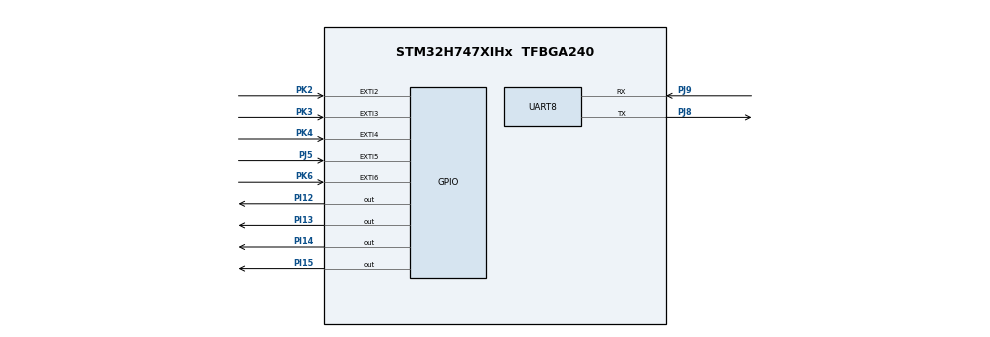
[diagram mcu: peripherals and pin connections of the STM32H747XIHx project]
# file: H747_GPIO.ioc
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Mcu.Family=STM32H7
PK3.Signal=GPXTI3
RCC.CortexFreq_Value=8000000
PJ9.Mode=Asynchronous
PI15.PinState=GPIO_PIN_SET
ProjectManager.StackSize=0x400
PK6.GPIO_PuPd=GPIO_NOPULL
PK6.PinAttribute=CortexM7
PK4.PinAttribute=CortexM7
PI13.PinState=GPIO_PIN_SET
RCC.HCLKFreq_Value=8000000
PI13.Signal=GPIO_Output
PJ5.GPIO_ModeDefaultEXTI=GPIO_MODE_IT_FALLING
NVIC2.PriorityGroup=NVIC_PRIORITYGROUP_4
PI12.PinAttribute=CortexM7
VP_SYS_M4_VS_Systick.Mode=SysTick
PK4.GPIO_ModeDefaultEXTI=GPIO_MODE_IT_FALLING
CortexM7.Pins=PK4,PK6,PK3,PI12,PI13,PI14,PK2,PI15,PJ5
CortexM7.IPs=BDMA\:I,CORTEX_M7\:I,DEBUG\:I,DMA\:I,FATFS_M7\:I,FREERTOS_M7\:I,IWDG1\:I,MDMA\:I,NVIC1\:I,OPENAMP_M7\:I,PDM2PCM_M7\:I,PWR\:I,RCC\:I,RESMGR_UTILITY\:I,SYS\:I,USB_DEVICE_M7\:I,USB_HOST_M7\:I,VREFBUF\:I,WWDG1\:I,UART8\:I
PK6.GPIO_ModeDefaultEXTI=GPIO_MODE_IT_FALLING
PJ5.PinAttribute=CortexM7
PJ5.GPIO_PuPd=GPIO_PULLDOWN
RCC.APB3Freq_Value=8000000
Mcu.Package=TFBGA240
PJ9.PinAttribute=CortexM7
PJ9.Signal=UART8_RX
PK2.GPIO_PuPd=GPIO_NOPULL
RCC.APB4Freq_Value=8000000
PK6.Signal=GPXTI6
PK4.Signal=GPXTI4
PK2.Signal=GPXTI2
PI14.PinState=GPIO_PIN_SET
RCC.D1CPRE=RCC_SYSCLK_DIV8
PJ8.Mode=Asynchronous
NVIC1.EXTI9_5_IRQn=true\:0\:0\:false\:false\:true\:true\:true
PI14.Signal=GPIO_Output
PI15.PinAttribute=CortexM7
PI14.PinAttribute=CortexM7
NVIC1.PriorityGroup=NVIC_PRIORITYGROUP_4
PI12.Signal=GPIO_Output
PJ8.PinAttribute=CortexM7
PK2.GPIO_ModeDefaultEXTI=GPIO_MODE_IT_FALLING
PK2.PinAttribute=CortexM7
ProjectManager.TargetToolchain=STM32CubeIDE
PI13.PinAttribute=CortexM7
NVIC1.EXTI2_IRQn=true\:0\:0\:false\:false\:true\:true\:true
RCC.USBFreq_Value=129000000
PK3.GPIO_PuPd=GPIO_NOPULL
board=custom
PK4.GPIO_PuPd=GPIO_NOPULL
RCC.APB2Freq_Value=8000000
PK3.PinAttribute=CortexM7
RCC.ADCFreq_Value=129000000
Mcu.Name=STM32H747XIHx
RCC.SYSCLKFreq_VALUE=64000000
PK3.GPIO_ModeDefaultEXTI=GPIO_MODE_IT_FALLING
NVIC1.EXTI4_IRQn=true\:0\:0\:false\:false\:true\:true\:true
PJ5.Signal=GPXTI5
PJ8.Signal=UART8_TX
ProjectManager.HeapSize=0x200
NVIC1.EXTI3_IRQn=true\:0\:0\:false\:false\:true\:true\:true
PI15.Signal=GPIO_Output
RCC.APB1Freq_Value=8000000
PI12.PinState=GPIO_PIN_SET
CortexM4.IPs=BDMA,CORTEX_M4\:I,DEBUG,DMA,FATFS_M4\:I,FREERTOS_M4\:I,IWDG2\:I,MDMA,NVIC2\:I,OPENAMP_M4\:I,PDM2PCM_M4\:I,PWR,RCC,RESMGR_UTILITY,SYS_M4\:I,USB_DEVICE_M4\:I,USB_HOST_M4\:I,VREFBUF,WWDG2\:I

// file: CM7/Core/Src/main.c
/* USER CODE BEGIN Header */
/**
  ******************************************************************************
  * @file           : main.c
  * @brief          : Main program body
  ******************************************************************************
  * @attention
  *
  * <h2><center>&copy; Copyright (c) 2020 STMicroelectronics.
  * All rights reserved.</center></h2>
  *
  * This software component is licensed by ST under BSD 3-Clause license,
  * the "License"; You may not use this file except in compliance with the
  * License. You may obtain a copy of the License at:
  *                        opensource.org/licenses/BSD-3-Clause
  *
  ******************************************************************************
  */
/* USER CODE END Header */
#include "main.h"
#include <stdio.h>

/* USER CODE BEGIN PD */

#define HSEM_ID_0 (0U) /* HW semaphore 0*/
/* USER CODE END PD */

UART_HandleTypeDef huart8;

/* USER CODE BEGIN PV */

int __io_putchar (int ch) {
	uint8_t c = ch;
	HAL_UART_Transmit(&huart8, &c, 1, HAL_MAX_DELAY);
	return ch;
}
void HAL_GPIO_EXTI_Callback(uint16_t GPIO_Pin)
{
	if(GPIO_Pin == GPIO_PIN_2){
		printf("***2***\r\n");
	}
	if(GPIO_Pin == GPIO_PIN_3){
		printf("***3***\r\n");
	}
	if(GPIO_Pin == GPIO_PIN_4){
		printf("***4***\r\n");
	}
	if(GPIO_Pin == GPIO_PIN_5){
		printf("***5***\r\n");
	}
}
/* USER CODE END PV */

void SystemClock_Config(void);
static void MX_GPIO_Init(void);
static void MX_UART8_Init(void);

int main(void)
{

/* USER CODE BEGIN Boot_Mode_Sequence_0 */
  int32_t timeout;
/* USER CODE END Boot_Mode_Sequence_0 */

/* USER CODE BEGIN Boot_Mode_Sequence_1 */
  /* Wait until CPU2 boots and enters in stop mode or timeout*/
  timeout = 0xFFFF;
  while((__HAL_RCC_GET_FLAG(RCC_FLAG_D2CKRDY) != RESET) && (timeout-- > 0));
  if ( timeout < 0 )
  {
  Error_Handler();
  }
/* USER CODE END Boot_Mode_Sequence_1 */
  /* MCU Configuration--------------------------------------------------------*/

  /* Reset of all peripherals, Initializes the Flash interface and the Systick. */
  HAL_Init();

  /* Configure the system clock */
  SystemClock_Config();
/* USER CODE BEGIN Boot_Mode_Sequence_2 */
/* When system initialization is finished, Cortex-M7 will release Cortex-M4 by means of
HSEM notification */
/*HW semaphore Clock enable*/
__HAL_RCC_HSEM_CLK_ENABLE();
/*Take HSEM */
HAL_HSEM_FastTake(HSEM_ID_0);
/*Release HSEM in order to notify the CPU2(CM4)*/
HAL_HSEM_Release(HSEM_ID_0,0);
/* wait until CPU2 wakes up from stop mode */
timeout = 0xFFFF;
while((__HAL_RCC_GET_FLAG(RCC_FLAG_D2CKRDY) == RESET) && (timeout-- > 0));
if ( timeout < 0 )
{
Error_Handler();
}
/* USER CODE END Boot_Mode_Sequence_2 */

  /* Initialize all configured peripherals */
  MX_GPIO_Init();
  MX_UART8_Init();

  /* Infinite loop */
  while (1)
  {

  }
}

void SystemClock_Config(void)
{
  RCC_OscInitTypeDef RCC_OscInitStruct = {0};
  RCC_ClkInitTypeDef RCC_ClkInitStruct = {0};
  RCC_PeriphCLKInitTypeDef PeriphClkInitStruct = {0};

  /** Supply configuration update enable
  */
  HAL_PWREx_ConfigSupply(PWR_LDO_SUPPLY);
  /** Configure the main internal regulator output voltage
  */
  __HAL_PWR_VOLTAGESCALING_CONFIG(PWR_REGULATOR_VOLTAGE_SCALE3);

  while(!__HAL_PWR_GET_FLAG(PWR_FLAG_VOSRDY)) {}
  /** Initializes the RCC Oscillators according to the specified parameters
  * in the RCC_OscInitTypeDef structure.
  */
  RCC_OscInitStruct.OscillatorType = RCC_OSCILLATORTYPE_HSI;
  RCC_OscInitStruct.HSIState = RCC_HSI_DIV1;
  RCC_OscInitStruct.HSICalibrationValue = RCC_HSICALIBRATION_DEFAULT;
  RCC_OscInitStruct.PLL.PLLState = RCC_PLL_NONE;
  if (HAL_RCC_OscConfig(&RCC_OscInitStruct) != HAL_OK)
  {
    Error_Handler();
  }
  /** Initializes the CPU, AHB and APB buses clocks
  */
  RCC_ClkInitStruct.ClockType = RCC_CLOCKTYPE_HCLK|RCC_CLOCKTYPE_SYSCLK
                              |RCC_CLOCKTYPE_PCLK1|RCC_CLOCKTYPE_PCLK2
                              |RCC_CLOCKTYPE_D3PCLK1|RCC_CLOCKTYPE_D1PCLK1;
  RCC_ClkInitStruct.SYSCLKSource = RCC_SYSCLKSOURCE_HSI;
  RCC_ClkInitStruct.SYSCLKDivider = RCC_SYSCLK_DIV8;
  RCC_ClkInitStruct.AHBCLKDivider = RCC_HCLK_DIV1;
  RCC_ClkInitStruct.APB3CLKDivider = RCC_APB3_DIV1;
  RCC_ClkInitStruct.APB1CLKDivider = RCC_APB1_DIV1;
  RCC_ClkInitStruct.APB2CLKDivider = RCC_APB2_DIV1;
  RCC_ClkInitStruct.APB4CLKDivider = RCC_APB4_DIV1;

  if (HAL_RCC_ClockConfig(&RCC_ClkInitStruct, FLASH_LATENCY_0) != HAL_OK)
  {
    Error_Handler();
  }
  PeriphClkInitStruct.PeriphClockSelection = RCC_PERIPHCLK_UART8;
  PeriphClkInitStruct.Usart234578ClockSelection = RCC_USART234578CLKSOURCE_D2PCLK1;
  if (HAL_RCCEx_PeriphCLKConfig(&PeriphClkInitStruct) != HAL_OK)
  {
    Error_Handler();
  }
}

static void MX_UART8_Init(void)
{

  huart8.Instance = UART8;
  huart8.Init.BaudRate = 115200;
  huart8.Init.WordLength = UART_WORDLENGTH_8B;
  huart8.Init.StopBits = UART_STOPBITS_1;
  huart8.Init.Parity = UART_PARITY_NONE;
  huart8.Init.Mode = UART_MODE_TX_RX;
  huart8.Init.HwFlowCtl = UART_HWCONTROL_NONE;
  huart8.Init.OverSampling = UART_OVERSAMPLING_16;
  huart8.Init.OneBitSampling = UART_ONE_BIT_SAMPLE_DISABLE;
  huart8.Init.ClockPrescaler = UART_PRESCALER_DIV1;
  huart8.AdvancedInit.AdvFeatureInit = UART_ADVFEATURE_NO_INIT;
  if (HAL_UART_Init(&huart8) != HAL_OK)
  {
    Error_Handler();
  }
  if (HAL_UARTEx_SetTxFifoThreshold(&huart8, UART_TXFIFO_THRESHOLD_1_8) != HAL_OK)
  {
    Error_Handler();
  }
  if (HAL_UARTEx_SetRxFifoThreshold(&huart8, UART_RXFIFO_THRESHOLD_1_8) != HAL_OK)
  {
    Error_Handler();
  }
  if (HAL_UARTEx_DisableFifoMode(&huart8) != HAL_OK)
  {
    Error_Handler();
  }

}

static void MX_GPIO_Init(void)
{
  GPIO_InitTypeDef GPIO_InitStruct = {0};

  /* GPIO Ports Clock Enable */
  __HAL_RCC_GPIOK_CLK_ENABLE();
  __HAL_RCC_GPIOI_CLK_ENABLE();
  __HAL_RCC_GPIOJ_CLK_ENABLE();

  /*Configure GPIO pin Output Level */
  HAL_GPIO_WritePin(GPIOI, GPIO_PIN_12|GPIO_PIN_13|GPIO_PIN_14|GPIO_PIN_15, GPIO_PIN_SET);

  /*Configure GPIO pins : PK4 PK6 PK3 PK2 */
  GPIO_InitStruct.Pin = GPIO_PIN_4|GPIO_PIN_6|GPIO_PIN_3|GPIO_PIN_2;
  GPIO_InitStruct.Mode = GPIO_MODE_IT_FALLING;
  GPIO_InitStruct.Pull = GPIO_NOPULL;
  HAL_GPIO_Init(GPIOK, &GPIO_InitStruct);

  /*Configure GPIO pins : PI12 PI13 PI14 PI15 */
  GPIO_InitStruct.Pin = GPIO_PIN_12|GPIO_PIN_13|GPIO_PIN_14|GPIO_PIN_15;
  GPIO_InitStruct.Mode = GPIO_MODE_OUTPUT_PP;
  GPIO_InitStruct.Pull = GPIO_NOPULL;
  GPIO_InitStruct.Speed = GPIO_SPEED_FREQ_LOW;
  HAL_GPIO_Init(GPIOI, &GPIO_InitStruct);

  /*Configure GPIO pin : PJ5 */
  GPIO_InitStruct.Pin = GPIO_PIN_5;
  GPIO_InitStruct.Mode = GPIO_MODE_IT_FALLING;
  GPIO_InitStruct.Pull = GPIO_PULLDOWN;
  HAL_GPIO_Init(GPIOJ, &GPIO_InitStruct);

  /* EXTI interrupt init*/
  HAL_NVIC_SetPriority(EXTI2_IRQn, 0, 0);
  HAL_NVIC_EnableIRQ(EXTI2_IRQn);

  HAL_NVIC_SetPriority(EXTI3_IRQn, 0, 0);
  HAL_NVIC_EnableIRQ(EXTI3_IRQn);

  HAL_NVIC_SetPriority(EXTI4_IRQn, 0, 0);
  HAL_NVIC_EnableIRQ(EXTI4_IRQn);

  HAL_NVIC_SetPriority(EXTI9_5_IRQn, 0, 0);
  HAL_NVIC_EnableIRQ(EXTI9_5_IRQn);

}

void Error_Handler(void)
{
}

/************************ (C) COPYRIGHT STMicroelectronics *****END OF FILE****/
